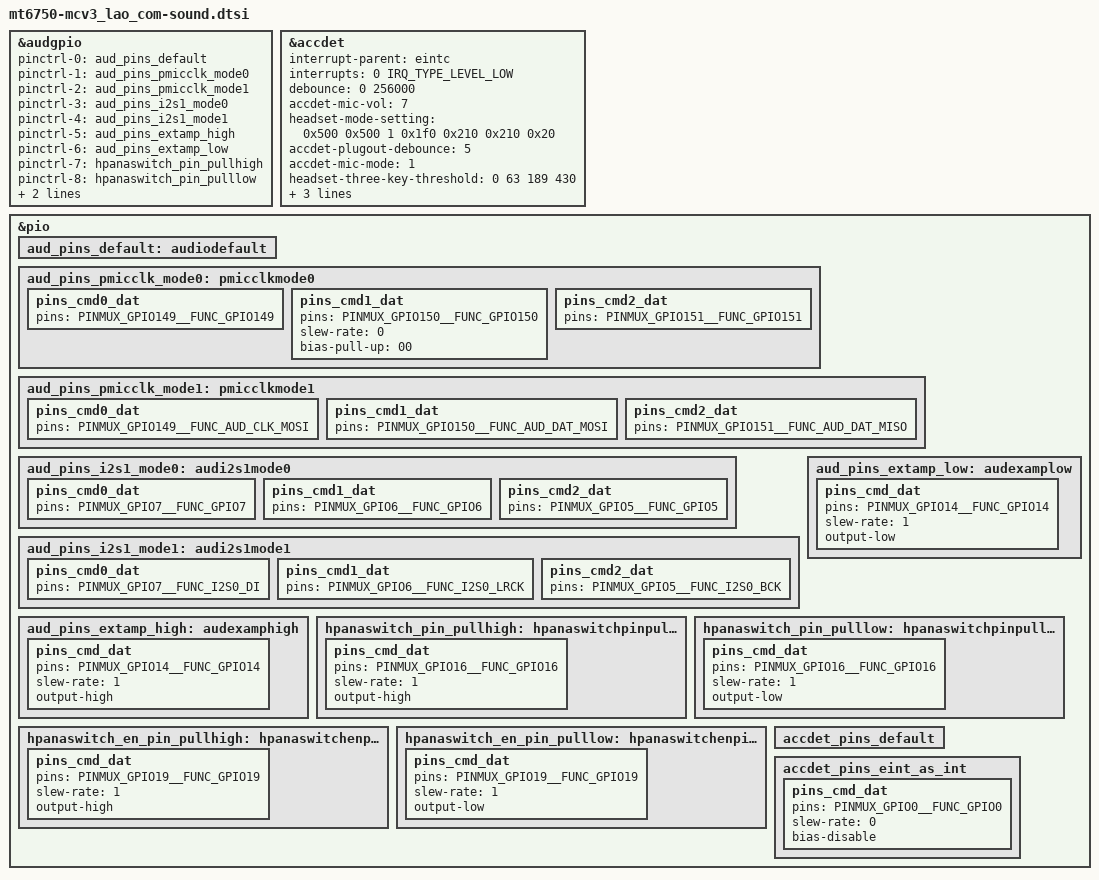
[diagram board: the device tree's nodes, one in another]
/*
 * LG Electronics CV3 sound device tree source
 *
 * Copyright (c) 2017 LG Electronics Co., Ltd.
 *              http://www.lge.com
 *
 */

/* AUDIO GPIO standardization */
&audgpio {
	pinctrl-names = "default", "audpmicclk-mode0", "audpmicclk-mode1", "audi2s1-mode0", "audi2s1-mode1",
					"extamp-pullhigh", "extamp-pulllow",
					"hpanaswitch-pullhigh", "hpanaswitch-pulllow", "hpanaswitch-en-pullhigh", "hpanaswitch-en-pulllow";
	pinctrl-0 = <&aud_pins_default>;
	pinctrl-1 = <&aud_pins_pmicclk_mode0>;
	pinctrl-2 = <&aud_pins_pmicclk_mode1>;
	pinctrl-3 = <&aud_pins_i2s1_mode0>;
	pinctrl-4 = <&aud_pins_i2s1_mode1>;
	pinctrl-5 = <&aud_pins_extamp_high>;
	pinctrl-6 = <&aud_pins_extamp_low>;
	pinctrl-7 = <&hpanaswitch_pin_pullhigh>;
	pinctrl-8 = <&hpanaswitch_pin_pulllow>;
	pinctrl-9 = <&hpanaswitch_en_pin_pullhigh>;
	pinctrl-10 = <&hpanaswitch_en_pin_pulllow>;
	status = "okay";
};

&accdet {
	interrupt-parent = <&eintc>;
	interrupts = <0 IRQ_TYPE_LEVEL_LOW>;
	debounce = <0 256000>;
	status = "okay";

	accdet-mic-vol = <7>;
	headset-mode-setting = <0x500 0x500 1 0x1f0 0x210 0x210 0x20>;
	accdet-plugout-debounce = <5>;
	/*1:ACC mode, 2:low cost without in bias, 6:low cost with in bias*/
	accdet-mic-mode = <1>;
	/*0--MD_MAX--UP_MAX--DW_MAX*/
	headset-three-key-threshold = <0 63 189 430>;
	/*0--MD_MAX--VOICE_MAX--UP_MAX--DW_MAX*/
	headset-four-key-threshold = <0 63 100 189 430>;

	pinctrl-names = "default", "state_eint_as_int";
	pinctrl-0 = <&accdet_pins_default>;
	pinctrl-1 = <&accdet_pins_eint_as_int>;
};

&pio {
	aud_pins_default: audiodefault {
	};

	aud_pins_pmicclk_mode0: pmicclkmode0 {
		pins_cmd0_dat {
			pins = <PINMUX_GPIO149__FUNC_GPIO149>;
		};
		pins_cmd1_dat {
			pins = <PINMUX_GPIO150__FUNC_GPIO150>;
			slew-rate = <0>;
			bias-pull-up = <00>;
		};
		pins_cmd2_dat {
			pins = <PINMUX_GPIO151__FUNC_GPIO151>;
		};
	};

	aud_pins_pmicclk_mode1: pmicclkmode1 {
		pins_cmd0_dat {
			pins = <PINMUX_GPIO149__FUNC_AUD_CLK_MOSI>;
		};
		pins_cmd1_dat {
			pins = <PINMUX_GPIO150__FUNC_AUD_DAT_MOSI>;
		};
		pins_cmd2_dat {
			pins = <PINMUX_GPIO151__FUNC_AUD_DAT_MISO>;
		};
	};

	aud_pins_i2s1_mode0: audi2s1mode0 {
		pins_cmd0_dat {
			pins = <PINMUX_GPIO7__FUNC_GPIO7>;
		};
		pins_cmd1_dat {
			pins = <PINMUX_GPIO6__FUNC_GPIO6>;
		};
		pins_cmd2_dat {
			pins = <PINMUX_GPIO5__FUNC_GPIO5>;
		};
	};

	aud_pins_i2s1_mode1: audi2s1mode1 {
		pins_cmd0_dat {
			pins = <PINMUX_GPIO7__FUNC_I2S0_DI>;
		};
		pins_cmd1_dat {
			pins = <PINMUX_GPIO6__FUNC_I2S0_LRCK>;
		};
		pins_cmd2_dat {
			pins = <PINMUX_GPIO5__FUNC_I2S0_BCK>;
		};
	};

	aud_pins_extamp_high: audexamphigh {
		pins_cmd_dat {
			pins = <PINMUX_GPIO14__FUNC_GPIO14>;
			slew-rate = <1>;
			output-high;
		};
	};

	aud_pins_extamp_low: audexamplow {
		pins_cmd_dat {
			pins = <PINMUX_GPIO14__FUNC_GPIO14>;
			slew-rate = <1>;
			output-low;
		};
	};

	hpanaswitch_pin_pullhigh: hpanaswitchpinpullhigh {
		pins_cmd_dat {
			pins = <PINMUX_GPIO16__FUNC_GPIO16>;
			slew-rate = <1>; /*direction 0:in, 1:out*/
			output-high;/*direction out used only. output_low or high*/
		};
	};

	hpanaswitch_pin_pulllow: hpanaswitchpinpulllow {
		pins_cmd_dat {
			pins = <PINMUX_GPIO16__FUNC_GPIO16>;
			slew-rate = <1>; /*direction 0:in, 1:out*/
			output-low;/*direction out used only. output_low or high*/
		};
	};

	hpanaswitch_en_pin_pullhigh: hpanaswitchenpinpullhigh {
		pins_cmd_dat {
			pins = <PINMUX_GPIO19__FUNC_GPIO19>;
			slew-rate = <1>; /*direction 0:in, 1:out*/
			output-high;/*direction out used only. output_low or high*/
		};
	};

	hpanaswitch_en_pin_pulllow: hpanaswitchenpinpulllow {
		pins_cmd_dat {
			pins = <PINMUX_GPIO19__FUNC_GPIO19>;
			slew-rate = <1>; /*direction 0:in, 1:out*/
			output-low;/*direction out used only. output_low or high*/
		};
	};

/* accdet */
	accdet_pins_default: accdet_pins_default {
	};
	accdet_pins_eint_as_int: accdet_pins_eint_as_int {
		pins_cmd_dat {
			pins = <PINMUX_GPIO0__FUNC_GPIO0>;
			slew-rate = <0>;
			bias-disable;
		};
	};
};

/* AUDIO end */
